# ATSAMD51P20A device description
Architecture: CORTEX-M4; Family: SAMD; Series: SAMD51
Registers are 32-bit, read-write, reset 0x0 unless marked. A register's access mark holds for its fields unless they carry their own. Offsets are from the block's base; [hi:lo] are bit positions; lines under a group give offsets from that group; {n}, {i} and the like mark numbered series; 'fields as' and 'values as' point back to an identical list.

## TAL — Trigger Allocator
Instances: TAL 0x4101E000
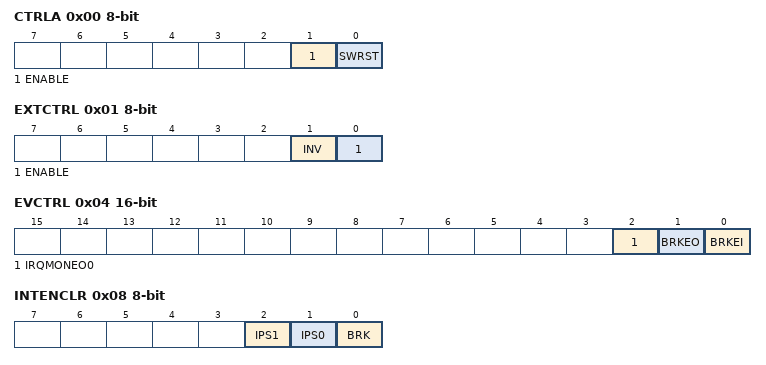
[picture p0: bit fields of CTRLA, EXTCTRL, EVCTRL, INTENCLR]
0x00 CTRLA 8-bit — Control A
  [1] ENABLE
  [0] SWRST — Software Reset
0x01 EXTCTRL 8-bit — External Break Control
  [1] INV — Invert BRK Pin
  [0] ENABLE — Enable BRK Pin
0x04 EVCTRL 16-bit — Event Control
  [2] IRQMONEO0 — Interrupt Request Monitor 0 Output Event Enable
  [1] BRKEO — Break Output Event Enable
  [0] BRKEI — Break Input Event Enable
0x08 INTENCLR 8-bit (atomic clear) — Interrupt Enable Clear
  [2] IPS1 — Inter-Processor Signal Interrupt Enable for CPU 1
  [1] IPS0 — Inter-Processor Signal Interrupt Enable for CPU 0
  [0] BRK — Break Interrupt Enable
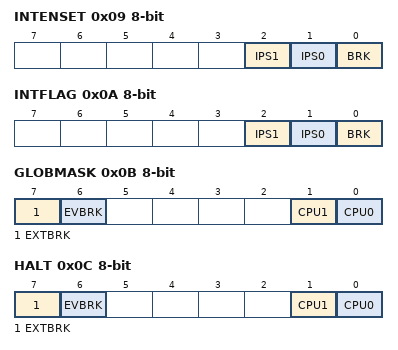
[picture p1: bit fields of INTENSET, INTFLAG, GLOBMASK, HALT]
0x09 INTENSET 8-bit (atomic set) — Interrupt Enable Set
  fields as INTENCLR
0x0A INTFLAG 8-bit (atomic clear) — Interrupt Flag Status and Clear
  [2] IPS1 — Inter-Processor Signal for CPU 1
  [1] IPS0 — Inter-Processor Signal for CPU 0
  [0] BRK — Break
0x0B GLOBMASK 8-bit — Global Break Requests Mask
  [7] EXTBRK — External Break Master
  [6] EVBRK — Event Break Master
  [1] CPU1 — CPU 1 Break Master
  [0] CPU0 — CPU 0 Break Master
0x0C HALT 8-bit wo — Debug Halt Request
  fields as GLOBMASK
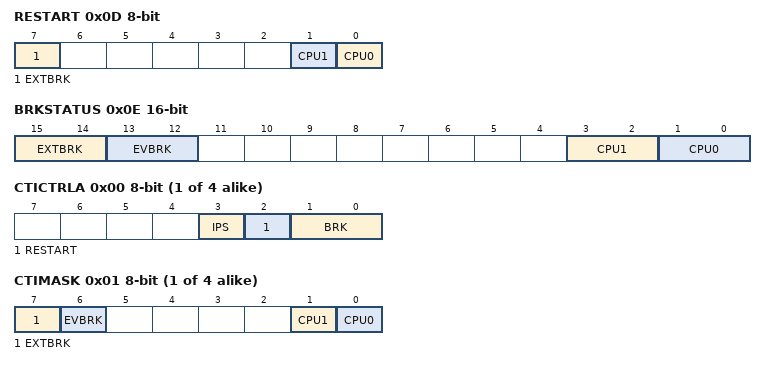
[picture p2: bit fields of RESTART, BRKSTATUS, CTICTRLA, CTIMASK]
0x0D RESTART 8-bit wo — Debug Restart Request
  [7] EXTBRK — External Break Master
  [1] CPU1 — CPU 1 Break Master
  [0] CPU0 — CPU 0 Break Master
0x0E BRKSTATUS 16-bit ro — Break Request Status
  [15:14] EXTBRK — External Break Request
  [13:12] EVBRK — Event Break Request
  [3:2] CPU1 — CPU 1 Break Request
  [1:0] CPU0 — CPU 0 Break Request
{0x10+2i} CTIS[{i}] (i=0..3) group
  0x00 CTICTRLA 8-bit — Cross-Trigger Interface n Control A
    [3] IPS — Action when inter-process resource freed
      0=EVENT (Generate CPU Event when awaited resource is freed.); 1=INTERRUPT (Generate Interrupt when awaited resource is freed.)
    [2] RESTART — Action when global restart issued
      0=RESTART (Restart when requested); 1=IGNORE (Ignore restart request)
    [1:0] BRK — Action when global break issued
      0=BREAK (Break when requested); 1=INTERRUPT (Trigger DBG interrupt instead of break); 2=IGNORE (Ignore break request)
  0x01 CTIMASK 8-bit — Cross-Trigger Interface n Mask
    fields as GLOBMASK
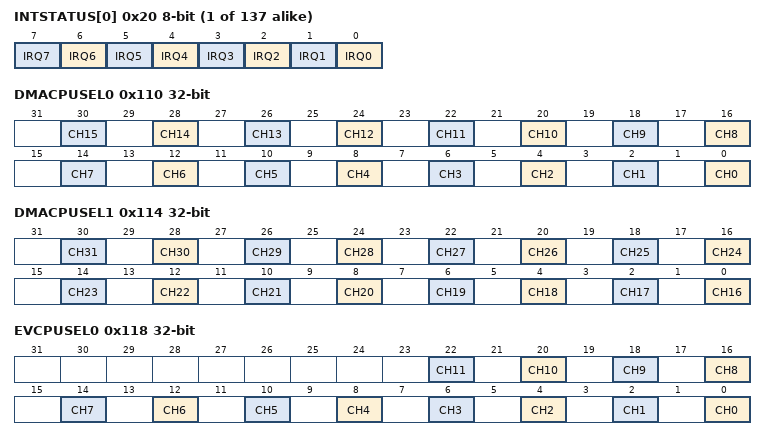
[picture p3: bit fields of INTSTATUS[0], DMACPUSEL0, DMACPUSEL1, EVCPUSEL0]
{0x20+i} INTSTATUS[{i}] (i=0..136) 8-bit ro — Interrupt n Status
  [n] IRQ{n} (n=0..7) — Interrupt Status for Interrupt Request {n} within Interrupt n
0x110 DMACPUSEL0 — DMA Channel Interrupts CPU Select 0
  [2n] CH{n} (n=0..15) — DMA Channel {n} Interrupt CPU Select
0x114 DMACPUSEL1 — DMA Channel Interrupts CPU Select 1
  [2n-32] CH{n} (n=16..31) — DMA Channel {n} Interrupt CPU Select
0x118 EVCPUSEL0 — EVSYS Channel Interrupts CPU Select 0
  [2n] CH{n} (n=0..11) — Event Channel {n} Interrupt CPU Select
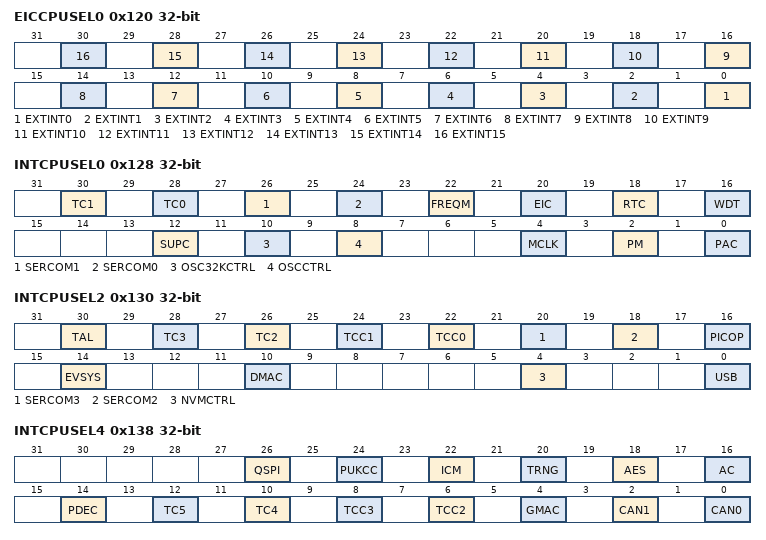
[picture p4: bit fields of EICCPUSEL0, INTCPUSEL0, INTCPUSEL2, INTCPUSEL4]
0x120 EICCPUSEL0 — EIC External Interrupts CPU Select 0
  [2n] EXTINT{n} (n=0..15) — External Interrupt {n} CPU Select
0x128 INTCPUSEL0 — Interrupts CPU Select 0
  [30] TC1 — TC1 Interrupt CPU Select
  [28] TC0 — TC0 Interrupt CPU Select
  [26] SERCOM1 — SERCOM1 Interrupt CPU Select
  [24] SERCOM0 — SERCOM0 Interrupt CPU Select
  [22] FREQM — FREQM Interrupt CPU Select
  [20] EIC — EIC Interrupt CPU Select
  [18] RTC — RTC Interrupt CPU Select
  [16] WDT — WDT Interrupt CPU Select
  [12] SUPC — SUPC Interrupt CPU Select
  [10] OSC32KCTRL — OSC32KCTRL Interrupt CPU Select
  [8] OSCCTRL — OSCCTRL Interrupt CPU Select
  [4] MCLK — MCLK Interrupt CPU Select
  [2] PM — PM Interrupt CPU Select
  [0] PAC — PAC Interrupt CPU Select
0x12C INTCPUSEL1 — Interrupts CPU Select 1
0x130 INTCPUSEL2 — Interrupts CPU Select 2
  [30] TAL — TAL Interrupt CPU Select
  [28] TC3 — TC3 Interrupt CPU Select
  [26] TC2 — TC2 Interrupt CPU Select
  [24] TCC1 — TCC1 Interrupt CPU Select
  [22] TCC0 — TCC0 Interrupt CPU Select
  [20] SERCOM3 — SERCOM3 Interrupt CPU Select
  [18] SERCOM2 — SERCOM2 Interrupt CPU Select
  [16] PICOP — PICOP Interrupt CPU Select
  [14] EVSYS — EVSYS Interrupt CPU Select
  [10] DMAC — DMAC Interrupt CPU Select
  [4] NVMCTRL — NVMCTRL Interrupt CPU Select
  [0] USB — USB Interrupt CPU Select
0x134 INTCPUSEL3 — Interrupts CPU Select 3
  [0] RAMECC — RAMECC Interrupt CPU Select
0x138 INTCPUSEL4 — Interrupts CPU Select 4
  [26] QSPI — QSPI Interrupt CPU Select
  [24] PUKCC — PUKCC Interrupt CPU Select
  [22] ICM — ICM Interrupt CPU Select
  [20] TRNG — TRNG Interrupt CPU Select
  [18] AES — AES Interrupt CPU Select
  [16] AC — AC Interrupt CPU Select
  [14] PDEC — PDEC Interrupt CPU Select
  [12] TC5 — TC5 Interrupt CPU Select
  [10] TC4 — TC4 Interrupt CPU Select
  [8] TCC3 — TCC3 Interrupt CPU Select
  [6] TCC2 — TCC2 Interrupt CPU Select
  [4] GMAC — GMAC Interrupt CPU Select
  [2] CAN1 — CAN1 Interrupt CPU Select
  [0] CAN0 — CAN0 Interrupt CPU Select
0x13C INTCPUSEL5 — Interrupts CPU Select 5
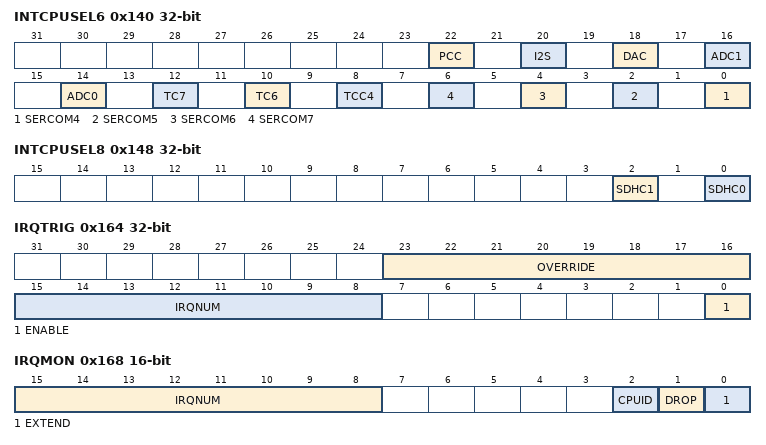
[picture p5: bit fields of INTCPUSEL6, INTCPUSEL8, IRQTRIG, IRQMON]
0x140 INTCPUSEL6 — Interrupts CPU Select 6
  [22] PCC — PCC Interrupt CPU Select
  [20] I2S — I2S Interrupt CPU Select
  [18] DAC — DAC Interrupt CPU Select
  [16] ADC1 — ADC1 Interrupt CPU Select
  [14] ADC0 — ADC0 Interrupt CPU Select
  [12] TC7 — TC7 Interrupt CPU Select
  [10] TC6 — TC6 Interrupt CPU Select
  [8] TCC4 — TCC4 Interrupt CPU Select
  [2n-8] SERCOM{n} (n=4..7) — SERCOM{n} Interrupt CPU Select
0x144 INTCPUSEL7 — Interrupts CPU Select 7
0x148 INTCPUSEL8 — Interrupts CPU Select 8
  [2] SDHC1 — SDHC1 Interrupt CPU Select
  [0] SDHC0 — SDHC0 Interrupt CPU Select
0x164 IRQTRIG — Interrupt Trigger
  [23:16] OVERRIDE — Interrupt Request Override Value
  [15:8] IRQNUM — Interrupt Request Number
  [0] ENABLE — Trigger Enable
0x168 IRQMON 16-bit — Interrupt Monitor Select
  [15:8] IRQNUM — Interrupt Request Number
  [2] CPUID — ID of CPU currently servicing this IRQ
  [1] DROP — Drop Shortened Events
  [0] EXTEND — Extended Interrupt Request
    0=NO (Event is Interrupt Request signal); 1=YES (Event is Interrupt Request signal extended until end of Interrupt Handler)
{0x180+0x20*i} CPUIRQS[{i}] (i=0..1) group
  {0x0+4j} CPUIRQS[{j}] (j=0..4) ro — Interrupt Status m for CPU n
    [31:0] CPUIRQS — Interrupt Requests for CPU n
{0x200+8i} SMASKS[{i}] (i=0..1) group
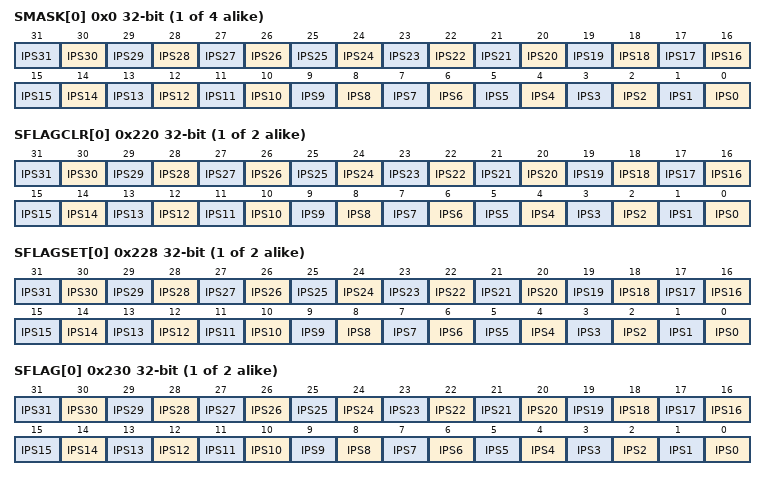
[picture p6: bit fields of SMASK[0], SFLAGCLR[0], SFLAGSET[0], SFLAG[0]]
  {0x0+4j} SMASK[{j}] (j=0..1) — Inter-Process Signal Mask m for CPU n
    [n] IPS{n} (n=0..31) — Inter-Process Signal {n}
{0x220+4i} SFLAGCLR[{i}] (i=0..1) wo (atomic clear of SFLAG) — Inter-Process Signal Flag Clear
  [n] IPS{n} (n=0..31) — Inter-Process Signal {n}
{0x228+4i} SFLAGSET[{i}] (i=0..1) wo (atomic set of SFLAG) — Inter-Process Signal Flag Set
  [n] IPS{n} (n=0..31) — Inter-Process Signal {n}
{0x230+4i} SFLAG[{i}] (i=0..1) ro — Inter-Process Signal Flag
  [n] IPS{n} (n=0..31) — Inter-Process Signal {n}
{0x300+i} SFLAGCLRR[{i}] (i=0..63) 8-bit — Inter-Process Signal Flag Bit n
  [0] IPS — Inter-Process Signal n
